# CM41x_M0 register map
Vendor: Analog Devices; Series: CM41x_M0; File version: 1p0
CPU: CM0 r0p0, little endian, MPU, FPU, 4 interrupt priority bits
Registers are 32-bit, read-write, reset 0x0 unless marked. A register's access mark holds for its fields unless they carry their own. Offsets are from the block's base; [hi:lo] are bit positions; {n}, {i} and the like mark numbered series; 'fields as' and 'values as' point back to an identical list.

## OCU0 — Oscillator Comparator Unit
Base 0x40015000
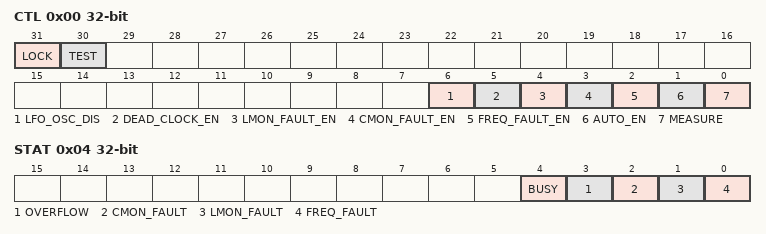
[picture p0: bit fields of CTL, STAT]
0x00 CTL — Control Register
  [31] LOCK range 0x00000000..0x00000001 — Enable LOCK
  [30] TEST range 0x00000000..0x00000001 — Test Mode Enable
  [6] LFO_OSC_DIS range 0x00000000..0x00000001 — External LFO Oscillator Disable
  [5] DEAD_CLOCK_EN range 0x00000000..0x00000001 — Asynchronous Fault Output Enable
  [4] LMON_FAULT_EN range 0x00000000..0x00000001 — LFO Monitor Fault Enable
  [3] CMON_FAULT_EN range 0x00000000..0x00000001 — Common Fault Enable
  [2] FREQ_FAULT_EN range 0x00000000..0x00000001 — Frequency Fault Enable
  [1] AUTO_EN range 0x00000000..0x00000001 — Automatic Monitor Enable
  [0] MEASURE range 0x00000000..0x00000001 — Measurement Cycle
0x04 STAT — Status Register
  [4] BUSY ro — Freq. measurement in progress
  [3] OVERFLOW range 0x00000000..0x00000001 — Freq. measurement overflow status
  [2] CMON_FAULT range 0x00000000..0x00000001 — Clkin monitor fault status
  [1] LMON_FAULT range 0x00000000..0x00000001 — LFO monitor fault status
  [0] FREQ_FAULT range 0x00000000..0x00000001 — Freq. fault status
0x08 CLKCNT — Frequency Measured Count Register
  [31:0] CLK_COUNT ro — Input Clock Counter Value
0x0C REFCNT — Reference Count Register
  [31:0] REF_COUNT range 0x00000000..0xFFFFFFFF — Reference Count
0x10 MINCNT — Minimum Limit Register
  [31:0] MIN_COUNT range 0x00000000..0xFFFFFFFF — Minimum Count
0x14 MAXCNT — Maximum Count Register
  [31:0] MAX_COUNT range 0x00000000..0xFFFFFFFF — Maximum Count
0x18 LMONCNT — LFO Monitor Reference Count Register
  [31:0] LMON_COUNT range 0x00000000..0xFFFFFFFF — LFO Monitor Count
0x1C CMONCNT — CLKIN Monitor Reference Count Register
  [31:0] CMON_COUNT range 0x00000000..0xFFFFFFFF — CLKIN Monitor Count

## TAPC
Base 0x40017000
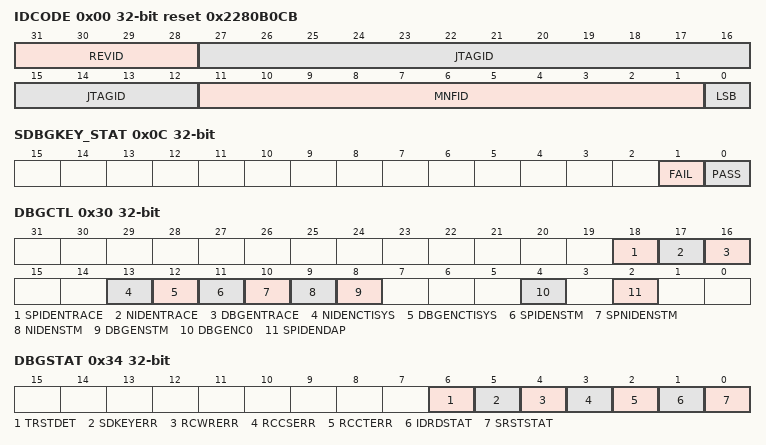
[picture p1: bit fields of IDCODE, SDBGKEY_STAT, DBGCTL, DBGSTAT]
0x00 IDCODE reset 0x2280B0CB
  [31:28] REVID ro — Silicon Revision
  [27:12] JTAGID ro
  [11:1] MNFID ro — Manufacturer ID
  [0] LSB ro — IDCODE LSB
0x04 USERCODE
  [31:0] VALUE ro — USERCODE[31:0]
0x08 SDBGKEY_CTL — Secure Debug Key Control Register
  [0] VALID range 0x00000000..0x00000001 — SDBGKEY Valid bit
0x0C SDBGKEY_STAT — Secure Debug Key Status Register
  [1] FAIL ro — SDBGKEY MATCH FAILED
  [0] PASS ro — SDBGKEY MATCH PASSED
{0x10+4i} SDBGKEY{i} (i=0..3) — Secure Debug Key {i} Register
  [31:0] VALUE range 0x00000000..0xFFFFFFFF — VALUE[{32i+31}:{32i}] SDBGKEY
0x30 DBGCTL — Debug Control Register
  [18] SPIDENTRACE range 0x00000000..0x00000001 — SPIDEN for ETR
  [17] NIDENTRACE range 0x00000000..0x00000001 — NIDEN for trace blocks
  [16] DBGENTRACE range 0x00000000..0x00000001 — DBGEN for trace blocks
  [13] NIDENCTISYS range 0x00000000..0x00000001 — NIDEN for CTISYS
  [12] DBGENCTISYS range 0x00000000..0x00000001 — DBGEN for CTISYS
  [11] SPIDENSTM range 0x00000000..0x00000001 — SPIDEN for STM
  [10] SPNIDENSTM range 0x00000000..0x00000001 — SPNIDEN for STM
  [9] NIDENSTM range 0x00000000..0x00000001 — NIDEN for STM
  [8] DBGENSTM range 0x00000000..0x00000001 — DBGEN for STM
  [4] DBGENC0 range 0x00000000..0x00000001 — DBGEN for Core 0
  [2] SPIDENDAP range 0x00000000..0x00000001 — SPIDEN for DAP
0x34 DBGSTAT — Debug Status Register
  [6] TRSTDET ro — Reset Detected
  [5] SDKEYERR range 0x00000000..0x00000001
  [4] RCWRERR range 0x00000000..0x00000001 — Run Control Write Update Error
  [3] RCCSERR range 0x00000000..0x00000001 — Run Control Serial Wire Error
  [2] RCCTERR range 0x00000000..0x00000001 — Run Control Message Error
  [1] IDRDSTAT range 0x00000000..0x00000001 — IDCODE Register Read Status
  [0] SRSTSTAT range 0x00000000..0x00000001 — SWK Block Hardware Reset
{0x50+4i} SDBGKEYCMP{i} (i=0..3) — Secure Debug Key {i} Compare Register
  [31:0] VALUE range 0x00000000..0xFFFFFFFF — SDBGKEYCMP word {i}
0x70 SDBGKEYID0 — Secure Debug Key 0 Identification Register
  [31:0] DATA range 0x00000000..0xFFFFFFFF — Part Specific User Key Identification Code
{0x70+4i} SDBGKEYID{i} (i=1..3) — Secure Debug Key {i} Key Identification Register
  fields as SDBGKEYID0
0xE0 SCMSG — System Run Control Message Register
  [31:0] VALUE range 0x00000000..0xFFFFFFFF — SC Message bits
0xE4 SCMSG_SET — System Run Control Message Set Register
  [31:0] VALUE range 0x00000000..0xFFFFFFFF — SC Message bits
0xE8 SCMSG_CLR — System Run Control Message Clear Register
  [31:0] VALUE range 0x00000000..0xFFFFFFFF — SC Message bits
0xEC SCMSG_TGL — System Run Control Message Toggle Register
  [31:0] VALUE range 0x00000000..0xFFFFFFFF — SC Message bits
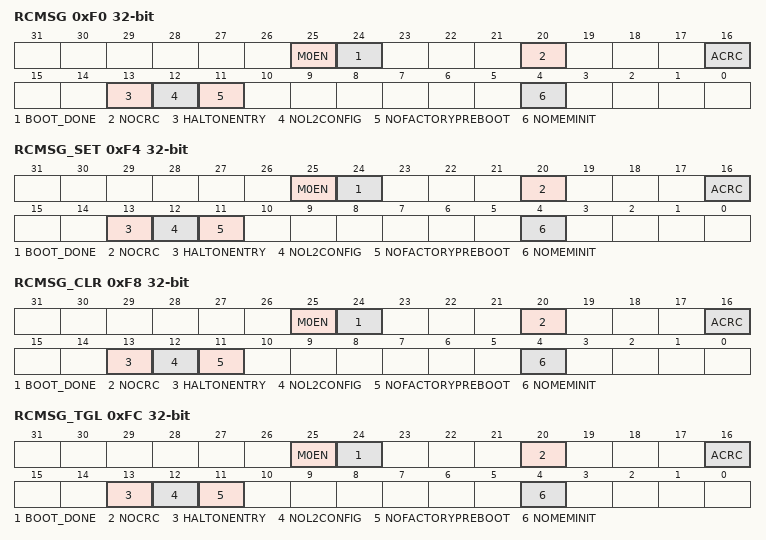
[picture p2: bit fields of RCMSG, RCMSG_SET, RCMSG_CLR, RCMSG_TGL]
0xF0 RCMSG — Run Control Message Register
  [25] M0EN range 0x00000000..0x00000001 — Cortex-M0 Enable
  [24] BOOT_DONE range 0x00000000..0x00000001
  [20] NOCRC range 0x00000000..0x00000001 — No CRC ROM Image
  [16] ACRC range 0x00000000..0x00000001 — Enable CRC
  [13] HALTONENTRY range 0x00000000..0x00000001
  [12] NOL2CONFIG range 0x00000000..0x00000001 — No L2 Memory Configuration
  [11] NOFACTORYPREBOOT range 0x00000000..0x00000001
  [4] NOMEMINIT range 0x00000000..0x00000001 — No Memory Initialization
0xF4 RCMSG_SET — Run Control Message Set Register
  fields as RCMSG
0xF8 RCMSG_CLR — Run Control Message Clear Register
  fields as RCMSG
0xFC RCMSG_TGL — Run Control Message Toggle Register
  fields as RCMSG
